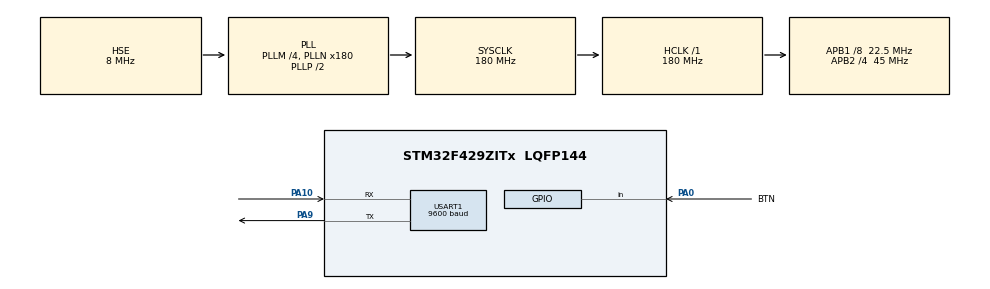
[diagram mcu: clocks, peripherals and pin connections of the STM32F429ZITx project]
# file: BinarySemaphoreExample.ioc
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FREERTOS.BinarySemaphores01=BinSem,Dynamic,NULL,Available
FREERTOS.Tasks01=normalTask,0,128,startNormalTask,Default,NULL,Dynamic,NULL,NULL;highTask,1,128,startHighTask,Default,NULL,Dynamic,NULL,NULL;lowTask,-1,128,startLowTask,Default,NULL,Dynamic,NULL,NULL
FREERTOS.configUSE_NEWLIB_REENTRANT=1
Mcu.Family=STM32F4
Mcu.Name=STM32F429ZITx
Mcu.Package=LQFP144
NVIC.PriorityGroup=NVIC_PRIORITYGROUP_4
NVIC.TIM1_UP_TIM10_IRQn=true\:15\:0\:false\:false\:true\:false\:false\:true\:true
NVIC.TimeBase=TIM1_UP_TIM10_IRQn
NVIC.TimeBaseIP=TIM1
PA0/WKUP.GPIO_Label=BTN
PA0/WKUP.Signal=GPIO_Input
PA10.Mode=Asynchronous
PA10.Signal=USART1_RX
PA9.Mode=Asynchronous
PA9.Signal=USART1_TX
PH0/OSC_IN.Mode=HSE-External-Oscillator
PH0/OSC_IN.Signal=RCC_OSC_IN
PH1/OSC_OUT.Mode=HSE-External-Oscillator
PH1/OSC_OUT.Signal=RCC_OSC_OUT
ProjectManager.HeapSize=0x200
ProjectManager.StackSize=0x400
ProjectManager.TargetToolchain=STM32CubeIDE
RCC.48MHZClocksFreq_Value=51428571.428571425
RCC.AHBFreq_Value=180000000
RCC.APB1CLKDivider=RCC_HCLK_DIV8
RCC.APB1Freq_Value=22500000
RCC.APB1TimFreq_Value=45000000
RCC.APB2CLKDivider=RCC_HCLK_DIV4
RCC.APB2Freq_Value=45000000
RCC.APB2TimFreq_Value=90000000
RCC.CortexFreq_Value=180000000
RCC.HCLKFreq_Value=180000000
RCC.HSE_VALUE=8000000
RCC.HSI_VALUE=16000000
RCC.LSE_VALUE=32768
RCC.PLLM=4
RCC.PLLN=180
RCC.PLLQ=7
RCC.PLLSourceVirtual=RCC_PLLSOURCE_HSE
RCC.SYSCLKFreq_VALUE=180000000
RCC.SYSCLKSource=RCC_SYSCLKSOURCE_PLLCLK
RCC.VCOOutputFreq_Value=360000000
USART1.BaudRate=9600
USART1.VirtualMode=VM_ASYNC
VP_FREERTOS_VS_CMSIS_V1.Mode=CMSIS_V1
VP_SYS_VS_tim1.Mode=TIM1
board=STM32F429I-DISC1

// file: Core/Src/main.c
/* USER CODE BEGIN Header */
/**
  ******************************************************************************
  * @file           : main.c
  * @brief          : Main program body
  ******************************************************************************
  * @attention
  *
  * Copyright (c) 2025 STMicroelectronics.
  * All rights reserved.
  *
  * This software is licensed under terms that can be found in the LICENSE file
  * in the root directory of this software component.
  * If no LICENSE file comes with this software, it is provided AS-IS.
  *
  ******************************************************************************
  */
/* USER CODE END Header */
#include "main.h"
#include "cmsis_os.h"
#include "stdio.h"
#include "string.h"

UART_HandleTypeDef huart1;

osThreadId normalTaskHandle;
osThreadId highTaskHandle;
osThreadId lowTaskHandle;
osSemaphoreId BinSemHandle;

void SystemClock_Config(void);
static void MX_GPIO_Init(void);
static void MX_USART1_UART_Init(void);
void startNormalTask(void const * argument);
void startHighTask(void const * argument);
void startLowTask(void const * argument);

int main(void)
{

  /* MCU Configuration--------------------------------------------------------*/

  /* Reset of all peripherals, Initializes the Flash interface and the Systick. */
  HAL_Init();

  /* Configure the system clock */
  SystemClock_Config();

  /* Initialize all configured peripherals */
  MX_GPIO_Init();
  MX_USART1_UART_Init();

  /* Create the semaphores(s) */
  /* definition and creation of BinSem */
  osSemaphoreDef(BinSem);
  BinSemHandle = osSemaphoreCreate(osSemaphore(BinSem), 1);

  /* Create the thread(s) */
  /* definition and creation of normalTask */
  osThreadDef(normalTask, startNormalTask, osPriorityNormal, 0, 128);
  normalTaskHandle = osThreadCreate(osThread(normalTask), NULL);

  /* definition and creation of highTask */
  osThreadDef(highTask, startHighTask, osPriorityAboveNormal, 0, 128);
  highTaskHandle = osThreadCreate(osThread(highTask), NULL);

  /* definition and creation of lowTask */
  osThreadDef(lowTask, startLowTask, osPriorityBelowNormal, 0, 128);
  lowTaskHandle = osThreadCreate(osThread(lowTask), NULL);

  /* Start scheduler */
  osKernelStart();

  /* We should never get here as control is now taken by the scheduler */

  /* Infinite loop */
  while (1)
  {

  }
}

void SystemClock_Config(void)
{
  RCC_OscInitTypeDef RCC_OscInitStruct = {0};
  RCC_ClkInitTypeDef RCC_ClkInitStruct = {0};

  /** Configure the main internal regulator output voltage
  */
  __HAL_RCC_PWR_CLK_ENABLE();
  __HAL_PWR_VOLTAGESCALING_CONFIG(PWR_REGULATOR_VOLTAGE_SCALE1);

  /** Initializes the RCC Oscillators according to the specified parameters
  * in the RCC_OscInitTypeDef structure.
  */
  RCC_OscInitStruct.OscillatorType = RCC_OSCILLATORTYPE_HSE;
  RCC_OscInitStruct.HSEState = RCC_HSE_ON;
  RCC_OscInitStruct.PLL.PLLState = RCC_PLL_ON;
  RCC_OscInitStruct.PLL.PLLSource = RCC_PLLSOURCE_HSE;
  RCC_OscInitStruct.PLL.PLLM = 4;
  RCC_OscInitStruct.PLL.PLLN = 180;
  RCC_OscInitStruct.PLL.PLLP = RCC_PLLP_DIV2;
  RCC_OscInitStruct.PLL.PLLQ = 7;
  if (HAL_RCC_OscConfig(&RCC_OscInitStruct) != HAL_OK)
  {
    Error_Handler();
  }

  /** Activate the Over-Drive mode
  */
  if (HAL_PWREx_EnableOverDrive() != HAL_OK)
  {
    Error_Handler();
  }

  /** Initializes the CPU, AHB and APB buses clocks
  */
  RCC_ClkInitStruct.ClockType = RCC_CLOCKTYPE_HCLK|RCC_CLOCKTYPE_SYSCLK
                              |RCC_CLOCKTYPE_PCLK1|RCC_CLOCKTYPE_PCLK2;
  RCC_ClkInitStruct.SYSCLKSource = RCC_SYSCLKSOURCE_PLLCLK;
  RCC_ClkInitStruct.AHBCLKDivider = RCC_SYSCLK_DIV1;
  RCC_ClkInitStruct.APB1CLKDivider = RCC_HCLK_DIV8;
  RCC_ClkInitStruct.APB2CLKDivider = RCC_HCLK_DIV4;

  if (HAL_RCC_ClockConfig(&RCC_ClkInitStruct, FLASH_LATENCY_5) != HAL_OK)
  {
    Error_Handler();
  }
}

static void MX_USART1_UART_Init(void)
{

  huart1.Instance = USART1;
  huart1.Init.BaudRate = 9600;
  huart1.Init.WordLength = UART_WORDLENGTH_8B;
  huart1.Init.StopBits = UART_STOPBITS_1;
  huart1.Init.Parity = UART_PARITY_NONE;
  huart1.Init.Mode = UART_MODE_TX_RX;
  huart1.Init.HwFlowCtl = UART_HWCONTROL_NONE;
  huart1.Init.OverSampling = UART_OVERSAMPLING_16;
  if (HAL_UART_Init(&huart1) != HAL_OK)
  {
    Error_Handler();
  }

}

static void MX_GPIO_Init(void)
{
  GPIO_InitTypeDef GPIO_InitStruct = {0};

  /* GPIO Ports Clock Enable */
  __HAL_RCC_GPIOH_CLK_ENABLE();
  __HAL_RCC_GPIOA_CLK_ENABLE();

  /*Configure GPIO pin : BTN_Pin */
  GPIO_InitStruct.Pin = BTN_Pin;
  GPIO_InitStruct.Mode = GPIO_MODE_INPUT;
  GPIO_InitStruct.Pull = GPIO_NOPULL;
  HAL_GPIO_Init(BTN_GPIO_Port, &GPIO_InitStruct);

}

void startNormalTask(void const * argument)
{
  /* USER CODE BEGIN 5 */
  /* Infinite loop */
  for(;;)
  {
	  char *str1 = "Entered NormalTask and waiting for semaphore\r\n";
	  HAL_UART_Transmit(&huart1, (uint8_t *) str1, strlen(str1), 100);
	  osSemaphoreWait(BinSemHandle, osWaitForever);
	  char *str3 = "Semaphore acquired by NormalTask\r\n";
	  HAL_UART_Transmit(&huart1, (uint8_t *) str3, strlen(str3), 100);
	  while(!HAL_GPIO_ReadPin(GPIOA, GPIO_PIN_0));	//Wait for btn input
	  char *str2 = "Leaving NormalTask and releasing Semaphore\r\n";
	  HAL_UART_Transmit(&huart1, (uint8_t *) str2, strlen(str2), 100);
	  osSemaphoreRelease(BinSemHandle);
	  osDelay(500);
  }
  /* USER CODE END 5 */
}

void startHighTask(void const * argument)
{
  /* USER CODE BEGIN startHighTask */
  /* Infinite loop */
  for(;;)
  {
	  char *str1 = "Entered HighTask and waiting for semaphore\r\n";
	  HAL_UART_Transmit(&huart1, (uint8_t *) str1, strlen(str1), 100);
	  osSemaphoreWait(BinSemHandle, osWaitForever);
	  char *str3 = "Semaphore acquired by HighTask\r\n";
	  HAL_UART_Transmit(&huart1, (uint8_t *) str3, strlen(str3), 100);
	  char *str2 = "Leaving HighTask and releasing Semaphore\r\n";
	  HAL_UART_Transmit(&huart1, (uint8_t *) str2, strlen(str2), 100);
	  osSemaphoreRelease(BinSemHandle);
	  osDelay(500);
  }
  /* USER CODE END startHighTask */
}

void startLowTask(void const * argument)
{
  /* USER CODE BEGIN startLowTask */
  /* Infinite loop */
  for(;;)
  {
	  char *str1 = "Entered LowTask\r\n";
	  HAL_UART_Transmit(&huart1, (uint8_t *) str1, strlen(str1), 100);
	  char *str2 = "Leaving LowTask\r\n";
	  HAL_UART_Transmit(&huart1, (uint8_t *) str2, strlen(str2), 100);
	  osDelay(500);
  }
  /* USER CODE END startLowTask */
}

void HAL_TIM_PeriodElapsedCallback(TIM_HandleTypeDef *htim)
{
  if (htim->Instance == TIM1) {
    HAL_IncTick();
  }
}

void Error_Handler(void)
{
  __disable_irq();
  while (1)
  {
  }
}
